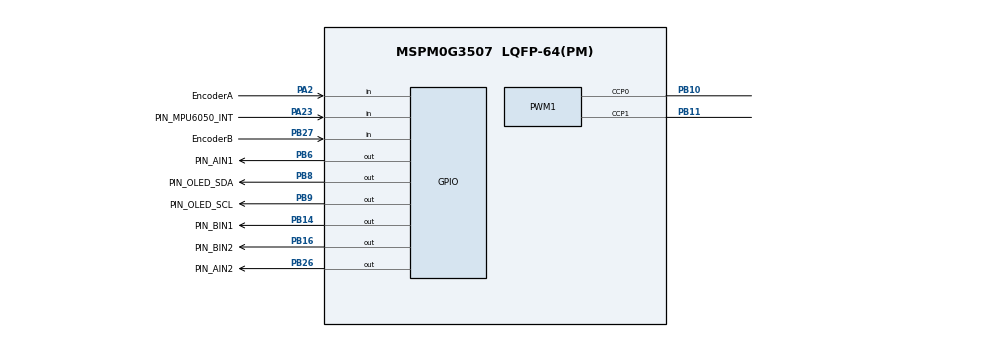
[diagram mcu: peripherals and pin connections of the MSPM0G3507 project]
/**
 * These arguments were used when this file was generated. They will be automatically applied on subsequent loads
 * via the GUI or CLI. Run CLI with '--help' for additional information on how to override these arguments.
 * @cliArgs --device "MSPM0G350X" --part "Default" --package "LQFP-64(PM)" --product "mspm0_sdk@2.05.00.05"
 * @v2CliArgs --device "MSPM0G3507" --package "LQFP-64(PM)" --product "mspm0_sdk@2.05.00.05"
 * @versions {"tool":"1.24.0+4110"}
 */

/**
 * Import the modules used in this configuration.
 */
const GPIO   = scripting.addModule("/ti/driverlib/GPIO", {}, false);
const GPIO1  = GPIO.addInstance();
const GPIO2  = GPIO.addInstance();
const GPIO3  = GPIO.addInstance();
const GPIO4  = GPIO.addInstance();
const GPIO5  = GPIO.addInstance();
const I2C    = scripting.addModule("/ti/driverlib/I2C", {}, false);
const I2C1   = I2C.addInstance();
const PWM    = scripting.addModule("/ti/driverlib/PWM", {}, false);
const PWM1   = PWM.addInstance();
const SYSCTL = scripting.addModule("/ti/driverlib/SYSCTL");

/**
 * Write custom configuration values to the imported modules.
 */
const divider7       = system.clockTree["PLL_PDIV"];
divider7.divideValue = 2;

const divider9       = system.clockTree["UDIV"];
divider9.divideValue = 2;

const multiplier2         = system.clockTree["PLL_QDIV"];
multiplier2.multiplyValue = 5;

const mux8       = system.clockTree["HSCLKMUX"];
mux8.inputSelect = "HSCLKMUX_SYSPLL2X";

GPIO1.$name                         = "GPIO_OLED";
GPIO1.associatedPins.create(2);
GPIO1.associatedPins[0].$name       = "PIN_OLED_SCL";
GPIO1.associatedPins[0].pin.$assign = "PB9";
GPIO1.associatedPins[1].$name       = "PIN_OLED_SDA";
GPIO1.associatedPins[1].pin.$assign = "PB8";

const Board = scripting.addModule("/ti/driverlib/Board", {}, false);

GPIO2.$name                               = "GPIO_MPU6050222";
GPIO2.associatedPins[0].$name             = "PIN_MPU6050_INT";
GPIO2.associatedPins[0].direction         = "INPUT";
GPIO2.associatedPins[0].internalResistor  = "PULL_UP";
GPIO2.associatedPins[0].interruptEn       = true;
GPIO2.associatedPins[0].interruptPriority = "3";
GPIO2.associatedPins[0].polarity          = "FALL";
GPIO2.associatedPins[0].pin.$assign       = "PA23";

GPIO3.$name                          = "GPIO_Motor1";
GPIO3.associatedPins.create(2);
GPIO3.associatedPins[0].$name        = "PIN_AIN1";
GPIO3.associatedPins[0].assignedPort = "PORTB";
GPIO3.associatedPins[0].pin.$assign  = "PB6";
GPIO3.associatedPins[1].$name        = "PIN_AIN2";
GPIO3.associatedPins[1].pin.$assign  = "PB26";

GPIO4.$name                         = "GPIO_Motor2";
GPIO4.port                          = "PORTB";
GPIO4.associatedPins.create(2);
GPIO4.associatedPins[0].$name       = "PIN_BIN1";
GPIO4.associatedPins[0].pin.$assign = "PB14";
GPIO4.associatedPins[1].$name       = "PIN_BIN2";
GPIO4.associatedPins[1].pin.$assign = "PB16";

GPIO5.$name                               = "GPIO_Encoder";
GPIO5.associatedPins.create(2);
GPIO5.associatedPins[0].direction         = "INPUT";
GPIO5.associatedPins[0].internalResistor  = "PULL_DOWN";
GPIO5.associatedPins[0].polarity          = "RISE";
GPIO5.associatedPins[0].interruptEn       = true;
GPIO5.associatedPins[0].interruptPriority = "1";
GPIO5.associatedPins[0].$name             = "EncoderA";
GPIO5.associatedPins[0].assignedPort      = "PORTA";
GPIO5.associatedPins[0].pin.$assign       = "PA2";
GPIO5.associatedPins[1].$name             = "EncoderB";
GPIO5.associatedPins[1].direction         = "INPUT";
GPIO5.associatedPins[1].internalResistor  = "PULL_DOWN";
GPIO5.associatedPins[1].interruptEn       = true;
GPIO5.associatedPins[1].interruptPriority = "1";
GPIO5.associatedPins[1].polarity          = "RISE";
GPIO5.associatedPins[1].assignedPort      = "PORTB";
GPIO5.associatedPins[1].pin.$assign       = "PB27";

I2C1.$name                             = "I2C_MPU6050";
I2C1.basicEnableController             = true;
I2C1.basicControllerStandardBusSpeed   = "Fast";
I2C1.sdaPinConfig.$name                = "ti_driverlib_gpio_GPIOPinGeneric0";
I2C1.sdaPinConfig.hideOutputInversion  = scripting.forceWrite(false);
I2C1.sdaPinConfig.onlyInternalResistor = scripting.forceWrite(false);
I2C1.sdaPinConfig.passedPeripheralType = scripting.forceWrite("Digital");
I2C1.sclPinConfig.$name                = "ti_driverlib_gpio_GPIOPinGeneric1";
I2C1.sclPinConfig.hideOutputInversion  = scripting.forceWrite(false);
I2C1.sclPinConfig.onlyInternalResistor = scripting.forceWrite(false);
I2C1.sclPinConfig.passedPeripheralType = scripting.forceWrite("Digital");

PWM1.clockDivider                       = 2;
PWM1.clockPrescale                      = 160;
PWM1.timerCount                         = 99;
PWM1.$name                              = "Motor";
PWM1.peripheral.$assign                 = "TIMG0";
PWM1.peripheral.ccp0Pin.$assign         = "PB10";
PWM1.peripheral.ccp1Pin.$assign         = "PB11";
PWM1.PWM_CHANNEL_0.$name                = "ti_driverlib_pwm_PWMTimerCC0";
PWM1.PWM_CHANNEL_0.ccValue              = 69;
PWM1.PWM_CHANNEL_0.dutyCycle            = 30;
PWM1.PWM_CHANNEL_1.$name                = "ti_driverlib_pwm_PWMTimerCC1";
PWM1.PWM_CHANNEL_1.dutyCycle            = 30;
PWM1.ccp0PinConfig.$name                = "ti_driverlib_gpio_GPIOPinGeneric2";
PWM1.ccp0PinConfig.direction            = scripting.forceWrite("OUTPUT");
PWM1.ccp0PinConfig.hideOutputInversion  = scripting.forceWrite(false);
PWM1.ccp0PinConfig.onlyInternalResistor = scripting.forceWrite(false);
PWM1.ccp0PinConfig.passedPeripheralType = scripting.forceWrite("Digital");
PWM1.ccp1PinConfig.$name                = "ti_driverlib_gpio_GPIOPinGeneric3";
PWM1.ccp1PinConfig.direction            = scripting.forceWrite("OUTPUT");
PWM1.ccp1PinConfig.hideOutputInversion  = scripting.forceWrite(false);
PWM1.ccp1PinConfig.onlyInternalResistor = scripting.forceWrite(false);
PWM1.ccp1PinConfig.passedPeripheralType = scripting.forceWrite("Digital");

SYSCTL.forceDefaultClkConfig = true;
SYSCTL.clockTreeEn           = true;
scripting.suppress("For best practices when the CPUCLK is running at 32MHz and above, clear the flash status bit using DL_FlashCTL_executeClearStatus\\(\\) before executing any flash operation\\. Otherwise there may be false positives\\.", SYSCTL);

/**
 * Pinmux solution for unlocked pins/peripherals. This ensures that minor changes to the automatic solver in a future
 * version of the tool will not impact the pinmux you originally saw.  These lines can be completely deleted in order to
 * re-solve from scratch.
 */
Board.peripheral.$suggestSolution          = "DEBUGSS";
Board.peripheral.swclkPin.$suggestSolution = "PA20";
Board.peripheral.swdioPin.$suggestSolution = "PA19";
I2C1.peripheral.$suggestSolution           = "I2C0";
I2C1.peripheral.sdaPin.$suggestSolution    = "PA0";
I2C1.peripheral.sclPin.$suggestSolution    = "PA1";
